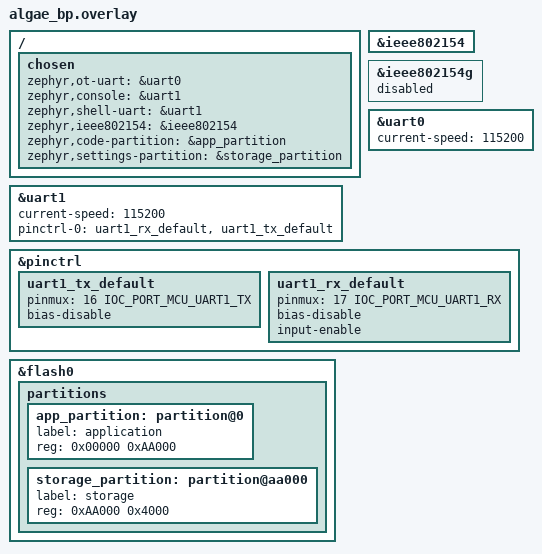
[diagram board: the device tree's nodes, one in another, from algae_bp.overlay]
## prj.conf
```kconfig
CONFIG_NETWORKING=y
CONFIG_NET_L2_OPENTHREAD=y

# Disable certain parts of Zephyr IPv6 stack
CONFIG_NET_IPV6_NBR_CACHE=n
CONFIG_NET_IPV6_MLD=n

# Use NVS as settings backend
CONFIG_NVS=y

# Disable boot banner
CONFIG_BOOT_BANNER=n

# Kernel options
CONFIG_MAIN_STACK_SIZE=2560

# Set OpenThread NCP architecture
CONFIG_OPENTHREAD_COPROCESSOR=y
# CONFIG_OPENTHREAD_COPROCESSOR_NCP=y

# Add features required for NCP
# CONFIG_OPENTHREAD_DIAG=y
# CONFIG_OPENTHREAD_DHCP6_SERVER=y
# CONFIG_OPENTHREAD_COMMISSIONER=y
# CONFIG_OPENTHREAD_BORDER_AGENT=y
# CONFIG_OPENTHREAD_BORDER_ROUTER=y
# CONFIG_OPENTHREAD_UDP_FORWARD=y
# CONFIG_OPENTHREAD_ENABLE_SERVICE=y

# This overlay switches from NCP to RCP, use in combination with prj.conf

CONFIG_OPENTHREAD_COPROCESSOR_NCP=n
CONFIG_OPENTHREAD_COPROCESSOR_RCP=y

CONFIG_NET_PKT_RX_COUNT=8
CONFIG_NET_PKT_TX_COUNT=8


# This overlay apply for beagleplay bundled cc1352p7

# Keep the application linker region outside NVS and the CCFG sector.
CONFIG_USE_DT_CODE_PARTITION=y

# Store Zephyr settings in the dedicated NVS partition.
CONFIG_FLASH=y
CONFIG_FLASH_MAP=y
# CONFIG_NVS=y
CONFIG_SETTINGS=y
CONFIG_SETTINGS_NVS=y
CONFIG_SETTINGS_NVS_SECTOR_SIZE_MULT=1
CONFIG_SETTINGS_NVS_SECTOR_COUNT=2

# For a dedicated RCP, commissioning belongs on the host
CONFIG_OPENTHREAD_COMMISSIONER=n
CONFIG_OPENTHREAD_BORDER_AGENT=n
```

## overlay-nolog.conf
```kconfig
# Copyright (c) 2024 Alexandre Bailon
# SPDX-License-Identifier: Apache-2.0

# Disable text output so it does not interfere with binary Spinel traffic.
CONFIG_CONSOLE=n
CONFIG_UART_CONSOLE=n
CONFIG_SHELL=n
CONFIG_LOG=n
CONFIG_PRINTK=n
CONFIG_BOOT_BANNER=n
```

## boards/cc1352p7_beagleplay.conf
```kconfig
# Keep the application linker region outside NVS and the CCFG sector.
CONFIG_USE_DT_CODE_PARTITION=y

# Store Zephyr settings in the dedicated NVS partition.
CONFIG_FLASH=y
CONFIG_FLASH_MAP=y
CONFIG_NVS=y
CONFIG_SETTINGS=y
CONFIG_SETTINGS_NVS=y
CONFIG_SETTINGS_NVS_SECTOR_SIZE_MULT=1
CONFIG_SETTINGS_NVS_SECTOR_COUNT=2

# For a dedicated RCP, commissioning belongs on the host
# CONFIG_OPENTHREAD_COMMISSIONER=n
# CONFIG_OPENTHREAD_BORDER_AGENT=n
```

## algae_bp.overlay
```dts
/*
 * Copyright (c) 2024 Alexandre Bailon
 *
 * SPDX-License-Identifier: Apache-2.0
 */

/ {
	chosen {
		zephyr,ot-uart = &uart0;

		zephyr,console = &uart1;
		zephyr,shell-uart = &uart1;

		/* default dts assigned to ieee802154g (sub-1 GHz) */
		zephyr,ieee802154 = &ieee802154;

		zephyr,code-partition = &app_partition;
		zephyr,settings-partition = &storage_partition;
	};
};

&ieee802154 {
	status = "okay";
};

&ieee802154g {
	status = "disabled";
};

&uart0 {
	current-speed = <115200>;
    /delete-property/ hw-flow-control;
	status = "okay";
};

&uart1 {
	current-speed = <115200>;
    /delete-property/ hw-flow-control;
	status = "okay";
	pinctrl-0 = <&uart1_rx_default &uart1_tx_default>;
	pinctrl-names = "default";
};

&pinctrl {
	/* default JTAG TDO */
	uart1_tx_default: uart1_tx_default {
		pinmux = <16 IOC_PORT_MCU_UART1_TX>;
		bias-disable;
	};

	/* default JTAG TDI */
	uart1_rx_default: uart1_rx_default {
		pinmux = <17 IOC_PORT_MCU_UART1_RX>;
		bias-disable;
		input-enable;
	};
};

&flash0 {
	partitions {
		/* about 680KiB */
		app_partition: partition@0 {
			label = "application";
			reg = <0x00000 0xAA000>;
		};

		/* about 16KiB */
		storage_partition: partition@aa000 {
			label = "storage";
			reg = <0xAA000 0x4000>;
		};
	};
};
```

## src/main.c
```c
/* main.c - OpenThread NCP */

/*
 * Copyright (c) 2020 Tridonic GmbH & Co KG
 *
 * SPDX-License-Identifier: Apache-2.0
 */

#include <zephyr/logging/log.h>
LOG_MODULE_REGISTER(ot_br, LOG_LEVEL_DBG);

#define APP_BANNER "***** OpenThread NCP on Zephyr %s *****"

#define log_m(_lvl, _fmt, ...) 

int main(void)
{
	LOG_INF(APP_BANNER, CONFIG_NET_SAMPLE_APPLICATION_VERSION);
	return 0;
}
```
